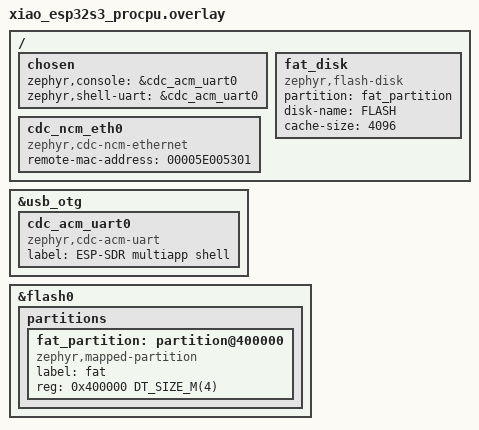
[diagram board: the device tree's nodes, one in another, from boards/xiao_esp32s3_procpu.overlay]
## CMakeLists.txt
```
# SPDX-License-Identifier: GPL-3.0-or-later
#
# multiapp (doc/multiapp.md): the other apps, built from their own sources as
# llext extensions, run on one host image.

cmake_minimum_required(VERSION 3.20.0)

find_package(Zephyr REQUIRED HINTS $ENV{ZEPHYR_BASE})
project(esp_sdr_multiapp)

include(${CMAKE_CURRENT_LIST_DIR}/../common/common.cmake)

target_include_directories(app PRIVATE include src)
target_sources(app PRIVATE src/main.c src/apps.c src/drive.c)

# Zephyr drops -Os from Xtensa extensions (cmake/compiler/gcc/target_xtensa.cmake);
# unoptimized, they need several times the stack and code.
list(REMOVE_ITEM LLEXT_REMOVE_FLAGS -Os)

set(apps_dir ${CMAKE_CURRENT_LIST_DIR}/..)
set(ext_dir ${PROJECT_BINARY_DIR}/llext)
set(ext_names)
set(ext_libs)
set(ext_files)
# The build id every app file carries (buildid.py, generated below).
set(build_id_bin ${ext_dir}/multiapp_build_id.bin)
set(build_id_h ${ext_dir}/multiapp_build_id.h)

# multiapp_extension(<name> SOURCES <files> [APP <dir>] [STACK <bytes>]
#                    [USB <MULTIAPP_USB_* mask>] [AREA])
#
# The extension <name>, include/multiapp/ext.h in front of each source. APP:
# the app's directory, for its CONFIG_APP_* values (appconfig.py). AREA: it
# has buffers in the area (ESP_SDR_HIGH_BUF_DEFINE()).
function(multiapp_extension name)
  cmake_parse_arguments(EXT "AREA" "APP;STACK;USB" "SOURCES" ${ARGN})
  if(NOT EXT_STACK)
    set(EXT_STACK 2048)
  endif()
  if(NOT EXT_USB)
    set(EXT_USB 0)
  endif()
  set(info ${ext_dir}/${name}_info.c)
  file(WRITE ${info}.tmp
    "/* Generated by apps/multiapp/CMakeLists.txt. */\n"
    "#include <zephyr/llext/symbol.h>\n"
    "#include <multiapp/multiapp.h>\n\n"
    "int main(void);\n\n"
    "const struct multiapp_info multiapp_info = {\n"
    "\t.abi = MULTIAPP_ABI,\n"
    "\t.name = \"${name}\",\n"
    "\t.main = main,\n"
    "};\n"
    "EXPORT_SYMBOL(multiapp_info);\n")
  configure_file(${info}.tmp ${info} COPYONLY)

  add_llext_target(${name}_ext
    OUTPUT  ${ext_dir}/${name}.llext
    SOURCES ${EXT_SOURCES} ${info}
  )
  # C only: an app may have assembly sources (link's esp-dsp FFT kernel).
  llext_compile_options(${name}_ext
    "$<$<COMPILE_LANGUAGE:C>:SHELL:-include ${CMAKE_CURRENT_FUNCTION_LIST_DIR}/include/multiapp/ext.h>")
  if(EXT_APP)
    set(app_config ${ext_dir}/${name}_config.h)
    set(app_confs ${EXT_APP}/Kconfig ${EXT_APP}/prj.conf)
    set(conf_args --conf ${EXT_APP}/prj.conf)
    # multiapp is built for the XIAO ESP32-S3 only.
    if(EXISTS ${EXT_APP}/boards/xiao_esp32s3_procpu.conf)
      list(APPEND app_confs ${EXT_APP}/boards/xiao_esp32s3_procpu.conf)
      list(APPEND conf_args --conf ${EXT_APP}/boards/xiao_esp32s3_procpu.conf)
    endif()
    execute_process(
      COMMAND ${PYTHON_EXECUTABLE} ${CMAKE_CURRENT_FUNCTION_LIST_DIR}/appconfig.py
              --kconfig ${EXT_APP}/Kconfig --host-config ${DOTCONFIG} ${conf_args}
              --out ${app_config}
      RESULT_VARIABLE ret
    )
    if(ret)
      message(FATAL_ERROR "multiapp: ${name}: appconfig.py failed")
    endif()
    set_property(DIRECTORY APPEND PROPERTY CMAKE_CONFIGURE_DEPENDS
      ${app_confs} ${CMAKE_CURRENT_FUNCTION_LIST_DIR}/appconfig.py)
    llext_compile_options(${name}_ext "$<$<COMPILE_LANGUAGE:C>:SHELL:-include ${app_config}>")
  endif()
  llext_compile_definitions(${name}_ext MULTIAPP_NAME=${name})
  llext_include_directories(${name}_ext
    ${CMAKE_CURRENT_FUNCTION_LIST_DIR}/include
    ${apps_dir}/common/include
  )
  # The file the host loads: the extension and its trailer (apptrail.py).
  set(file ${ext_dir}/files/${name}.llext)
  add_custom_command(
    OUTPUT ${file}
    COMMAND ${CMAKE_COMMAND} -E make_directory ${ext_dir}/files
    COMMAND ${PYTHON_EXECUTABLE} ${CMAKE_CURRENT_FUNCTION_LIST_DIR}/apptrail.py
            --stack ${EXT_STACK} --build-id ${build_id_bin} ${ext_dir}/${name}.llext ${file}
    DEPENDS ${CMAKE_CURRENT_FUNCTION_LIST_DIR}/apptrail.py ${ext_dir}/${name}.llext
            ${build_id_bin}
  )
  generate_inc_file_for_target(app ${file}
    ${ZEPHYR_BINARY_DIR}/include/generated/multiapp_${name}.inc)

  set(ext_names ${ext_names} ${name} PARENT_SCOPE)
  set(ext_usb_${name} ${EXT_USB} PARENT_SCOPE)
  if(EXT_AREA)
    set(ext_area_${name} true PARENT_SCOPE)
  else()
    set(ext_area_${name} false PARENT_SCOPE)
  endif()
  set(ext_libs ${ext_libs} $<TARGET_FILE:${name}_ext_llext_lib> PARENT_SCOPE)
  set(ext_files ${ext_files} ${file} PARENT_SCOPE)
endfunction()

multiapp_extension(hello SOURCES ${CMAKE_CURRENT_LIST_DIR}/ext/hello.c)
multiapp_extension(capture STACK 4096 SOURCES ${apps_dir}/capture/src/main.c)
multiapp_extension(rfprobe STACK 2048 SOURCES ${apps_dir}/rfprobe/src/main.c)
multiapp_extension(wpan STACK 1536 SOURCES ${apps_dir}/wpan/src/main.c)
set(stream ${apps_dir}/stream/src)
multiapp_extension(stream APP ${apps_dir}/stream STACK 2048 USB 1 # MULTIAPP_USB_NCM
  SOURCES ${stream}/main.c ${stream}/vrt_rx.c ${stream}/iq_pack.c
          ${stream}/shell.c ${stream}/vrt_tx.c ${stream}/transport_udp.c)
set_source_files_properties(${stream}/iq_pack.c PROPERTIES COMPILE_OPTIONS -O3)

# osmosdr: its vendor USB class is in the host (src/osmosdr.c), the rest an
# extension whose USB blocks and ring and USB thread stacks are in the area.
set(osmosdr ${apps_dir}/osmosdr/src)
multiapp_extension(osmosdr APP ${apps_dir}/osmosdr STACK 1536 USB 2 AREA # MULTIAPP_USB_VENDOR
  SOURCES ${osmosdr}/main.c ${osmosdr}/sdr.c ${osmosdr}/shell.c)
set_source_files_properties(${osmosdr}/sdr.c PROPERTIES COMPILE_OPTIONS "-O3;-ffp-contract=fast")
target_sources(app PRIVATE src/osmosdr.c ${osmosdr}/usb_sdr.c)
set_source_files_properties(src/osmosdr.c ${osmosdr}/usb_sdr.c PROPERTIES
  INCLUDE_DIRECTORIES ${osmosdr})

# link, with the flags of its own build (apps/link/CMakeLists.txt).
set(link ${apps_dir}/link/src)
set(esp_dsp ${WEST_TOPDIR}/modules/lib/esp-dsp)
set(esp_dsp_fft ${esp_dsp}/modules/fft/float/dsps_fft2r_fc32_aes3_.S)
multiapp_extension(link APP ${apps_dir}/link STACK 2048
  SOURCES ${link}/main.c ${link}/mac.c ${link}/perf.c ${link}/qam.c ${link}/rs.c
          ${link}/hamming.c ${link}/ofdm.c ${link}/ofdm_frame.c ${link}/ofdm_test.c
          ${esp_dsp_fft})
llext_compile_definitions(link_ext QAM_SPS=CONFIG_APP_SPS)
set_source_files_properties(${link}/qam.c ${link}/ofdm.c PROPERTIES
  COMPILE_OPTIONS "-O3;-ffp-contract=fast")
set_source_files_properties(${link}/rs.c ${link}/hamming.c PROPERTIES COMPILE_OPTIONS -O3)
set_source_files_properties(${esp_dsp_fft} PROPERTIES
  COMPILE_DEFINITIONS CONFIG_IDF_TARGET_ESP32S3=1
  INCLUDE_DIRECTORIES ${esp_dsp}/modules/fft/include)

# Buffers of the apps that never run the receive ring, in its bank 0.
zephyr_linker_sources(DATA_SECTIONS multiapp_bank0.ld)

# The FAT volume with the extensions' files (src/drive.c), for west dfu --storage.
dt_nodelabel(fat_node NODELABEL fat_partition)
dt_reg_size(fat_size PATH ${fat_node})
set(fat_img ${PROJECT_BINARY_DIR}/multiapp_fat.img)
add_custom_command(
  OUTPUT ${fat_img}
  COMMAND ${PYTHON_EXECUTABLE} ${CMAKE_CURRENT_LIST_DIR}/mkfat.py --size ${fat_size}
          --out ${fat_img} ${ext_files}
  DEPENDS ${CMAKE_CURRENT_LIST_DIR}/mkfat.py ${ext_files}
  COMMENT "FAT volume of the multiapp extensions"
)
add_custom_target(multiapp_fat ALL DEPENDS ${fat_img})

# The embedded extensions, and what the host exports to them.
set(embedded ${ext_dir}/embedded.c)
set(embedded_text "/* Generated by apps/multiapp/CMakeLists.txt. */\n\n#include \"apps.h\"\n#include <multiapp/multiapp.h>\n\n")
# Without CONFIG_MULTIAPP_EMBEDDED the table keeps only what a boot needs
# before it loads the app's file (name, USB profile, area).
if(CONFIG_MULTIAPP_EMBEDDED)
  foreach(name ${ext_names})
    string(APPEND embedded_text
      "static const uint8_t ${name}_llext[] __aligned(4) = {\n#include \"multiapp_${name}.inc\"\n};\n")
  endforeach()
endif()
string(APPEND embedded_text "\nconst struct multiapp_embedded multiapp_embedded[] = {\n")
foreach(name ${ext_names})
  if(CONFIG_MULTIAPP_EMBEDDED)
    set(elf "${name}_llext, sizeof(${name}_llext)")
  else()
    set(elf "NULL, 0")
  endif()
  string(APPEND embedded_text
    "\t{\"${name}\", ${elf}, ${ext_usb_${name}}, ${ext_area_${name}}},\n")
endforeach()
list(LENGTH ext_names ext_count)
string(APPEND embedded_text "};\n\nconst size_t multiapp_embedded_count = ${ext_count};\n")
file(WRITE ${embedded}.tmp "${embedded_text}")
configure_file(${embedded}.tmp ${embedded} COPYONLY)

set(exports ${ext_dir}/exports.c)
set(logs ${ext_dir}/logs.c)
set(objects ${ext_dir}/objects.c)
add_custom_command(
  OUTPUT ${exports} ${logs} ${objects}
  COMMAND ${PYTHON_EXECUTABLE} ${CMAKE_CURRENT_LIST_DIR}/exports.py
          --exports ${exports} --logs ${logs} --objects ${objects}
          --area-size ${CONFIG_MULTIAPP_AREA_SIZE} ${ext_libs}
  DEPENDS ${CMAKE_CURRENT_LIST_DIR}/exports.py ${ext_libs}
  COMMENT "Exporting what the multiapp extensions import"
)
target_sources(app PRIVATE ${embedded} ${exports} ${logs} ${objects})

# The build id (buildid.py): a hash of what host and extensions must agree on.
set(id_dirs ${ZEPHYR_BASE}/include ${CMAKE_CURRENT_LIST_DIR}/include ${apps_dir}/common/include
            ${apps_dir}/../include)
set(id_headers)
set(id_args)
foreach(dir ${id_dirs})
  file(GLOB_RECURSE headers ${dir}/*.h)
  list(APPEND id_headers ${headers})
  list(APPEND id_args --dir ${dir})
endforeach()
add_custom_command(
  OUTPUT ${build_id_h} ${build_id_bin}
  COMMAND ${PYTHON_EXECUTABLE} ${CMAKE_CURRENT_LIST_DIR}/buildid.py
          --out-h ${build_id_h} --out-bin ${build_id_bin}
          --compiler "${CMAKE_C_COMPILER_ID} ${CMAKE_C_COMPILER_VERSION}"
          --file ${AUTOCONF_H} --file ${DEVICETREE_GENERATED_H} --file ${exports} ${id_args}
  DEPENDS ${CMAKE_CURRENT_LIST_DIR}/buildid.py ${AUTOCONF_H} ${DEVICETREE_GENERATED_H}
          ${exports} ${id_headers}
  COMMENT "multiapp build id"
)
target_sources(app PRIVATE ${build_id_h})
target_include_directories(app PRIVATE ${ext_dir})
```

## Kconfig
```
# SPDX-License-Identifier: GPL-3.0-or-later

mainmenu "multiapp: one firmware that runs the others"

config MULTIAPP_INSTR_HEAP_KB
	int "Extension code heap in PSRAM, KiB"
	default 256

config MULTIAPP_DATA_HEAP_KB
	int "Extension data heap in PSRAM, KiB"
	default 512
	help
	  The extensions' data, read-only data and bss, and llext's metadata.

config MULTIAPP_STACK_SIZE
	int "Largest stack of an app's main() thread"
	default 4096
	help
	  One stack in PSRAM for every app's main(); an app that asks for more
	  (multiapp_extension() STACK) is refused.

config MULTIAPP_EMBEDDED
	bool "Apps built into the image too"
	default y
	help
	  Each app is also built into the image, loaded when the FAT volume has
	  no good file for it. Without, an app runs only from its file.

config MULTIAPP_FILE_MAX_KB
	int "Largest app file, KiB"
	default 192
	help
	  The PSRAM buffer a boot reads the app's file into before loading it.

config MULTIAPP_AREA_SIZE
	int "Bytes of internal RAM the apps share, one per boot"
	default 24576
	help
	  In the high region: the buffers an app defines with
	  ESP_SDR_HIGH_BUF_DEFINE() and ESP_SDR_HIGH_STACK_DEFINE() (osmosdr's
	  USB blocks, ring and USB thread stacks), or in other boots the 802.15.4
	  driver's buffers.

config MULTIAPP_AUTOSTART
	string "App to start at boot"
	default ""
	help
	  Started when no "app run" request is pending from before a reset.
	  Empty: none, start one with "app run <name>".

config LLEXT_EXPORT_SYMBOL_GROUP_MULTIAPP
	def_bool y
	help
	  What the embedded extensions import, exported by exports.py. Zephyr's
	  default groups (every syscall, a libc subset) stay off: what they
	  export is kept by the linker, kernel code in IRAM included.

# USB shell and DFU.
rsource "../common/Kconfig"
source "samples/subsys/usb/common/Kconfig.sample_usbd"

source "Kconfig.zephyr"
```

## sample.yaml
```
sample:
  name: ESP-SDR multiapp
  description: >-
    One firmware that runs the other apps as loadable extensions
    (doc/multiapp.md): capture, rfprobe, wpan, stream, osmosdr and link,
    loaded from files on a FAT volume, with built-in copies
common:
  tags: esp-sdr
  sysbuild: true
  platform_allow:
    - xiao_esp32s3/esp32s3/procpu
  integration_platforms:
    - xiao_esp32s3/esp32s3/procpu
tests:
  # The console is on USB CDC-ACM; "app run <name>" there (see README).
  sample.esp_sdr.multiapp:
    build_only: true
  # On the desk with the boards attached (pytest/test_multiapp.py): the image and
  # its FAT volume (scripts/twister-flash.py), booting into hello from its file.
  sample.esp_sdr.multiapp.hil:
    harness: pytest
    harness_config:
      pytest_dut_scope: module
    extra_args:
      - multiapp_EXTRA_CONF_FILE=hil.conf
    timeout: 600
```

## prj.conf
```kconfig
# The Wi-Fi driver brings the radio up at boot; nothing may scan or connect.
CONFIG_NETWORKING=y
CONFIG_WIFI=y
CONFIG_ESP32_WIFI_STA_POWER_SAVE_NONE=y
CONFIG_ESP_SDR=y

CONFIG_SHELL=y
CONFIG_LOG=y
CONFIG_LOG_MODE_DEFERRED=y

# Loadable extensions, code and data in PSRAM heaps; the code runs at its
# instruction bus alias (src/apps.c).
CONFIG_LLEXT=y
CONFIG_LLEXT_HEAP_DYNAMIC=y
CONFIG_LLEXT_EXEC_ALIAS=y
# Every global of an extension, not only EXPORT_SYMBOL()s: the host finds the
# hooks an app defines by name (app_usb_dfu_prepare()).
CONFIG_LLEXT_IMPORT_ALL_GLOBALS=y
# The host exports exactly what its extensions import (exports.py, group MULTIAPP).
CONFIG_LLEXT_EXPORT_DEFAULT_GROUPS=n
CONFIG_LLEXT_LOG_LEVEL_ERR=y

# What the apps need from the host: capture's float output, rfprobe's dumps.
CONFIG_PICOLIBC_IO_FLOAT=y
CONFIG_BASE64=y
```

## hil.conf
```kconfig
# The desk check (sample.esp_sdr.multiapp.hil): every boot starts hello.
CONFIG_MULTIAPP_AUTOSTART="hello"
```

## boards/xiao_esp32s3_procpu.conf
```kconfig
# SMP and octal PSRAM as the apps that run on both cores (stream, link,
# osmosdr, wpan); the Wi-Fi heap goes to PSRAM.
CONFIG_FPU=y
CONFIG_FPU_SHARING=y
CONFIG_SMP=y
CONFIG_ESP_SPIRAM=y
CONFIG_SPIRAM_MODE_OCT=y
CONFIG_ESP_WIFI_HEAP_SPIRAM=y
# The network and Wi-Fi drivers' stacks and packet pools too: internal RAM
# is for the dump banks.
CONFIG_ESP32_WIFI_NET_ALLOC_SPIRAM=y
CONFIG_SCHED_CPU_MASK=y
# The apps use the radio, not Wi-Fi traffic: the fewest static receive buffers
# (about 1.6 KB of system heap each), so no A-MPDU receive, whose window may be
# at most twice their number.
CONFIG_ESP32_WIFI_STATIC_RX_BUFFER_NUM=2
CONFIG_ESP32_WIFI_AMPDU_RX_ENABLED=n
CONFIG_ESP32_WIFI_MGMT_SBUF_NUM=8
CONFIG_ESP32_WIFI_EVENT_TASK_STACK_SIZE=1024
CONFIG_NET_MGMT_EVENT_STACK_SIZE=1024
CONFIG_HEAP_MEM_POOL_IGNORE_MIN=y
# Peak 12216 bytes in every app (`kernel heap`), nearly all of it the Wi-Fi driver's.
CONFIG_HEAP_MEM_POOL_SIZE=13312
CONFIG_SYS_HEAP_RUNTIME_STATS=y
CONFIG_RESET_ON_FATAL_ERROR=y
# A hung app resets the board instead of needing a replug; "app crash" tells.
CONFIG_APP_LIVENESS_WATCHDOG=y

# USB device on the OTG port: shell on CDC-ACM, DFU with sysbuild/MCUboot.
CONFIG_USB_DEVICE_STACK_NEXT=y
CONFIG_SAMPLE_USBD_PRODUCT="ESP-SDR multiapp"
CONFIG_SAMPLE_USBD_PID=0x0005
CONFIG_USBD_LOG_LEVEL_WRN=y
CONFIG_UDC_DRIVER_LOG_LEVEL_WRN=y
CONFIG_USBD_CDC_ACM_CLASS=y
# CDC-ACM carries the console and the shell: its own logging must stay off
# (doc/testing.md: usbd_cdc_acm.c's #warning is fatal under twister).
CONFIG_USBD_CDC_ACM_LOG_LEVEL_OFF=y
CONFIG_CDC_ACM_SERIAL_INITIALIZE_AT_BOOT=n
CONFIG_LOG_BACKEND_UART=n
CONFIG_USBD_CDC_ACM_WORKQUEUE=y
CONFIG_KERNEL_SHELL=y
CONFIG_SHELL_BACKEND_SERIAL_LOG_MESSAGE_QUEUE_SIZE=256
CONFIG_HWINFO=y

# The radio as wpan uses it: transmit through the DAC, the gapless receive ring
# (three dump banks: the DRAM image must end below 0x3fcb0000) and the
# 802.15.4 software radio without the L2.
CONFIG_ESP_SDR_TX=y
CONFIG_ESP_SDR_TX_DAC=y
CONFIG_ESP_SDR_TX_DAC_HIGH_RAM=y
CONFIG_ESP_SDR_RING=y
CONFIG_ESP_SDR_IEEE802154=y
# Its buffers live in the area osmosdr's boots use instead (src/apps.c).
CONFIG_ESP_SDR_IEEE802154_HIGH_RAM_APP=y
CONFIG_IEEE802154=y
CONFIG_NET_L2_IEEE802154=n
CONFIG_NET_L2_WIFI_SHELL=n

# Internal RAM for the three banks: stacks sized for an 80 % peak with every app
# exercised (`kernel thread stacks`, `app info`, `app crash`).
CONFIG_NET_RX_STACK_SIZE=1024
# Peak 1120 (radio init), in every boot.
CONFIG_MAIN_STACK_SIZE=1536
# Peak 880 (stream).
CONFIG_SYSTEM_WORKQUEUE_STACK_SIZE=1152
# Peak 288.
CONFIG_IDLE_STACK_SIZE=384
# Peak 560.
CONFIG_ISR_STACK_SIZE=768
# The apps' commands run here: link's need 2.3 KB (ofdm bench), as its own.
CONFIG_SHELL_STACK_SIZE=3072
# Peak 544.
CONFIG_LOG_PROCESS_THREAD_STACK_SIZE=704
# Peak 688.
CONFIG_ESP32_TIMER_TASK_STACK_SIZE=896
CONFIG_LOG_BUFFER_SIZE=448
CONFIG_SHELL_CMD_BUFF_SIZE=96
CONFIG_SHELL_HISTORY=n
CONFIG_DEVICE_SHELL=n
CONFIG_DATE_SHELL=n
# Peak 1008, in a DFU download (it writes the flash).
CONFIG_USBD_THREAD_STACK_SIZE=1280
# Peak 528.
CONFIG_UDC_DWC2_STACK_SIZE=704
# Peak 640.
CONFIG_USBD_CDC_ACM_STACK_SIZE=832
# llext links the whole kernel; nothing here sends mailbox messages.
CONFIG_NUM_MBOX_ASYNC_MSGS=0

# stream's USB profile: VITA 49.2 over UDP/IPv6 on CDC-NCM, with the
# network pools the stream app sizes (in PSRAM, see above). The NCM endpoint
# buffers live in bank 0 (multiapp_bank0.ld).
CONFIG_LIBVRT=y
CONFIG_USBD_CDC_NCM_CLASS=y
CONFIG_USBD_CDC_NCM_RECV_NTB_MAX_SIZE=8192
CONFIG_USBD_CDC_NCM_MAX_DGRAM_PER_NTB=5
CONFIG_USBD_CDC_NCM_SEND_NTB_MAX_SIZE=4608
CONFIG_USBD_CDC_NCM_SEND_MAX_DGRAM_PER_NTB=3
CONFIG_NET_IPV6=y
CONFIG_NET_IPV4=n
CONFIG_NET_UDP=y
CONFIG_NET_SOCKETS=y
CONFIG_NET_CONTEXT_RCVTIMEO=y
CONFIG_NET_IF_MAX_IPV6_COUNT=2
CONFIG_NET_BUF_DATA_SIZE=256
CONFIG_NET_PKT_TX_COUNT=24
CONFIG_NET_BUF_TX_COUNT=32
CONFIG_NET_PKT_RX_COUNT=16
CONFIG_NET_BUF_RX_COUNT=48
CONFIG_NET_STATISTICS=y
CONFIG_NET_STATISTICS_PER_INTERFACE=y
CONFIG_NET_SHELL=y
# Two sockets on one link: fewer contexts and neighbours than the defaults.
CONFIG_NET_MAX_CONTEXTS=4
CONFIG_NET_IPV6_MAX_NEIGHBORS=4

# The apps as files on a FAT volume (src/drive.c): read only, by the host,
# before USB starts; long names (".llext" is not 8.3), one file at a time.
CONFIG_FILE_SYSTEM=y
CONFIG_FAT_FILESYSTEM_ELM=y
CONFIG_FS_FATFS_MOUNT_MKFS=n
CONFIG_FS_FATFS_NUM_FILES=1
CONFIG_FS_FATFS_NUM_DIRS=1
CONFIG_FS_FATFS_LFN=y
CONFIG_FS_FATFS_LFN_MODE_BSS=y
CONFIG_FS_FATFS_MAX_LFN=32
CONFIG_DISK_DRIVER_FLASH=y
CONFIG_FLASHDISK_LOG_LEVEL_WRN=y
CONFIG_FS_LOG_LEVEL_WRN=y
# The app files' CRC (crc32_ieee()).
CONFIG_CRC=y
# The volume as a USB drive in boots without an app: one SCSI buffer (in
# bank 0), the thread writes the flash so its stack stays internal (peak 880).
CONFIG_USBD_MSC_CLASS=y
CONFIG_USBD_MSC_DOUBLE_BUFFERING=n
CONFIG_USBD_MSC_STACK_SIZE=1152
CONFIG_USBD_MSC_LOG_LEVEL_WRN=y
```

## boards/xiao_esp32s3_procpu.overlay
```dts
/*
 * SPDX-License-Identifier: GPL-3.0-or-later
 */

/ {
	chosen {
		zephyr,console = &cdc_acm_uart0;
		zephyr,shell-uart = &cdc_acm_uart0;
	};

	/* The apps as files: the FAT volume, block device "FLASH". */
	fat_disk: fat_disk {
		compatible = "zephyr,flash-disk";
		partition = <&fat_partition>;
		disk-name = "FLASH";
		cache-size = <4096>;
	};

	/* stream's USB network function; the host side gets MAC 00:00:5e:00:53:01. */
	cdc_ncm_eth0: cdc_ncm_eth0 {
		compatible = "zephyr,cdc-ncm-ethernet";
		remote-mac-address = "00005E005301";
	};
};

zephyr_udc0: &usb_otg {
	status = "okay";

	/* Console, shell and logs while OTG owns the USB port. */
	cdc_acm_uart0: cdc_acm_uart0 {
		compatible = "zephyr,cdc-acm-uart";
		label = "ESP-SDR multiapp shell";
	};
};

/* The upper half of the 8 MB flash, which the board's 4 MB partition table leaves out. */
&flash0 {
	partitions {
		fat_partition: partition@400000 {
			compatible = "zephyr,mapped-partition";
			label = "fat";
			reg = <0x400000 DT_SIZE_M(4)>;
		};
	};
};
```

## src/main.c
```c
/*
 * SPDX-License-Identifier: GPL-3.0-or-later
 *
 * multiapp host (doc/multiapp.md): the USB shell and DFU, the radio, and the
 * apps built as extensions (apps.c).
 */

#include <zephyr/app_version.h>
#include <zephyr/kernel.h>

#include <esp_sdr/esp_sdr.h>

#include "app_cpu.h"
#include "app_usb.h"
#include "apps.h"

int main(void)
{
	int ret;

	printk("multiapp %s\n", APP_VERSION_STRING);
	/* Before USB: its interrupt lands on the CPU that allocates it, CPU 1 is the radio's. */
	app_cpu_pin_system_threads(0);
	ret = esp_sdr_init();
	if (ret != 0) {
		printk("multiapp: radio init failed (%d)\n", ret);
	}
	printk("multiapp: ready\n");
	/*
	 * The files while bank 0 and the flash are the host's alone, then the app
	 * before USB, whose classes call its handlers (osmosdr's).
	 */
	(void)multiapp_drive_scan();
	if (!multiapp_boot()) {
		/* No app: the volume goes to the PC as a USB drive. */
		(void)multiapp_drive_export();
	}
	/* The USB shell and DFU, and the trial watchdog that reverts an image that hangs. */
	if (app_usb_init() != 0) {
		printk("multiapp: usb init failed\n");
	}
	multiapp_note_main_stack();
	return 0;
}
```

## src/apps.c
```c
/*
 * SPDX-License-Identifier: GPL-3.0-or-later
 *
 * Runs one app per boot as an llext extension (doc/multiapp.md): loads it
 * into PSRAM, runs its constructors (include/multiapp/ext.h) and starts its
 * main() in a thread. Starting another app reboots into it.
 */

#include <errno.h>
#include <stdio.h>
#include <string.h>

#include <zephyr/app_version.h>
#include <zephyr/init.h>
#include <zephyr/kernel.h>
#include <zephyr/llext/buf_loader.h>
#include <zephyr/llext/llext.h>
#include <zephyr/logging/log.h>
#include <zephyr/shell/shell.h>
#include <zephyr/sys/crc.h>
#include <zephyr/sys/reboot.h>
#include <zephyr/usb/usbd.h>

#include <esp_attr.h>
#include <esp_rom_sys.h>
#include <rom/cache.h>

#include <esp_sdr/esp_sdr.h>
#if defined(CONFIG_ESP_SDR_IEEE802154)
#include <esp_sdr/ieee154_esp_sdr.h>
#endif

#include <multiapp/multiapp.h>

#include "multiapp_build_id.h"

#include "app_crash.h"
#include "app_usb.h"
#include "apps.h"

LOG_MODULE_REGISTER(multiapp, LOG_LEVEL_INF);

/* One MMU table maps both buses: PSRAM at 0x3c000000 + x executes at 0x42000000 + x. */
#define IBUS_DBUS_OFFSET 0x06000000

#define ROOTS_MAX       4
#define REQUEST_MAGIC   0x6d617070U /* "mapp" */
#define TRIED_MAGIC     0x74726964U /* "trid": the boot that tried it has started */
#define REBOOT_DELAY_MS 100

static EXT_RAM_BSS_ATTR uint8_t instr_heap[KB(CONFIG_MULTIAPP_INSTR_HEAP_KB)] __aligned(64);
static EXT_RAM_BSS_ATTR uint8_t data_heap[KB(CONFIG_MULTIAPP_DATA_HEAP_KB)] __aligned(64);

/* PSRAM like the app's data: internal RAM is kept for the dump banks. */
static Z_KERNEL_STACK_DEFINE_IN(app_stack, CONFIG_MULTIAPP_STACK_SIZE, EXT_RAM_BSS_ATTR);
static struct k_thread app_thread;

static EXT_RAM_BSS_ATTR struct llext_buf_loader loader;
static struct llext *loaded;
static const struct multiapp_info *loaded_info;
static const char *loaded_source; /* "file" or "built-in" */

/* What this host's apps carry in their trailers (buildid.py). */
static const uint8_t build_id[] = MULTIAPP_BUILD_ID;

/* The app's file, read whole before llext sees it (drive.c). */
static EXT_RAM_BSS_ATTR uint8_t file_buf[KB(CONFIG_MULTIAPP_FILE_MAX_KB)] __aligned(4);
static const struct shell_static_entry *roots[ROOTS_MAX];
static size_t root_count;

/* The app for the next boot and how far its boot got; survives a software reset. */
static RTC_NOINIT_ATTR struct {
	uint32_t magic;
	char name[24];
	uint32_t step;
} request;

enum boot_step {
	STEP_REQUESTED,
	STEP_LOADING,
	STEP_CONSTRUCTORS,
	STEP_MAIN,
	STEP_RUNNING,
};

static const char *const step_names[] = {"requested", "loading", "constructors", "main",
					 "running"};

/* What the previous boot left: the request it tried and the step it reached. */
static char tried_name[sizeof(request.name)];
static uint32_t tried_step;
static bool tried;

/* This boot's app, from a request or CONFIG_MULTIAPP_AUTOSTART, and its USB profile. */
static char boot_name[sizeof(request.name)];
static uint32_t usb_profile;
static int boot_ret;

/*
 * Internal RAM for one user per boot: the boot's app if it has buffers there
 * (ESP_SDR_HIGH_BUF_DEFINE(), exports.py), else the 802.15.4 driver.
 */
uint8_t multiapp_area[CONFIG_MULTIAPP_AREA_SIZE] __aligned(16) ESP_SDR_HIGH_RAM;
static const struct multiapp_embedded *area_app;

#if defined(CONFIG_ESP_SDR_IEEE802154_HIGH_RAM_APP)
void *ieee154_esp_sdr_high_ram(size_t size)
{
	if (area_app != NULL || size > sizeof(multiapp_area)) {
		return NULL;
	}
	return multiapp_area;
}
#endif

/* Before the devices: the area's user and the USB profile follow the boot's app. */
static int boot_pick(void)
{
	const struct multiapp_embedded *app;

	if (request.magic == TRIED_MAGIC) {
		/* The boot that tried an app ended before "app run" or a reset: report it. */
		tried = true;
		tried_step = request.step;
		memcpy(tried_name, request.name, sizeof(tried_name));
		tried_name[sizeof(tried_name) - 1] = '\0';
		request.magic = 0;
	}
	if (request.magic == REQUEST_MAGIC) {
		request.magic = TRIED_MAGIC;
		request.step = STEP_REQUESTED;
		memcpy(boot_name, request.name, sizeof(boot_name));
		boot_name[sizeof(boot_name) - 1] = '\0';
	} else if (!(tried && tried_step < STEP_RUNNING &&
		     strcmp(tried_name, CONFIG_MULTIAPP_AUTOSTART) == 0)) {
		/* Tried like a request, so one that never gets running is skipped once. */
		strncpy(boot_name, CONFIG_MULTIAPP_AUTOSTART, sizeof(boot_name) - 1);
		if (boot_name[0] != '\0') {
			request.magic = TRIED_MAGIC;
			request.step = STEP_REQUESTED;
			memcpy(request.name, boot_name, sizeof(request.name));
		}
	}
	app = multiapp_embedded_find(boot_name);
	usb_profile = app != NULL ? app->usb : MULTIAPP_USB_MSC;
	area_app = app != NULL && app->area ? app : NULL;
	return 0;
}
SYS_INIT(boot_pick, PRE_KERNEL_1, 0);

static int heaps_init(void)
{
	return llext_heap_init_harvard_exec(instr_heap, sizeof(instr_heap), data_heap,
					    sizeof(data_heap), IBUS_DBUS_OFFSET);
}
SYS_INIT(heaps_init, APPLICATION, 0);

/* Only the boot's app's classes: the OTG controller has too few IN endpoints for all. */
void app_usb_classes(struct usbd_context *ctx)
{
	if (IS_ENABLED(CONFIG_USBD_CDC_NCM_CLASS) && (usb_profile & MULTIAPP_USB_NCM) == 0U) {
		(void)usbd_unregister_class(ctx, "cdc_ncm_0", USBD_SPEED_FS, 1);
	}
	if ((usb_profile & MULTIAPP_USB_VENDOR) == 0U) {
		(void)usbd_unregister_class(ctx, "esp_sdr_usb", USBD_SPEED_FS, 1);
	}
	if (IS_ENABLED(CONFIG_USBD_MSC_CLASS) && (usb_profile & MULTIAPP_USB_MSC) == 0U) {
		(void)usbd_unregister_class(ctx, "msc_0", USBD_SPEED_FS, 1);
	}
}

void multiapp_shell_register(const struct shell_static_entry *root)
{
	if (root_count == ARRAY_SIZE(roots)) {
		LOG_ERR("no room for root command %s", root->syntax);
		return;
	}
	roots[root_count++] = root;
}

static const struct shell_static_entry *root_find(const char *name)
{
	for (size_t i = 0; i < root_count; i++) {
		if (strcmp(roots[i]->syntax, name) == 0) {
			return roots[i];
		}
	}
	return NULL;
}

const struct multiapp_embedded *multiapp_embedded_find(const char *name)
{
	for (size_t i = 0; i < multiapp_embedded_count; i++) {
		if (strcmp(multiapp_embedded[i].name, name) == 0) {
			return &multiapp_embedded[i];
		}
	}
	return NULL;
}

/* llext wrote the code through the data bus, and the ESP cache driver has no icache ops. */
static void sync_text(const struct llext *ext)
{
	uintptr_t text = (uintptr_t)ext->mem[LLEXT_MEM_TEXT];
	size_t size = ext->mem_size[LLEXT_MEM_TEXT];

	Cache_WriteBack_Addr(text, size);
	Cache_Invalidate_Addr(text + IBUS_DBUS_OFFSET, size);
}

/* Record how far this boot's app got, until the next "app run" or reset. */
static void boot_step(enum boot_step step)
{
	if (request.magic == TRIED_MAGIC) {
		request.step = step;
	}
}

static void app_main(void *p1, void *p2, void *p3)
{
	int (*entry)(void) = p1;
	int ret;

	ARG_UNUSED(p2);
	ARG_UNUSED(p3);
	ret = entry();
	boot_step(STEP_RUNNING);
	LOG_INF("%s: main returned %d", loaded_info->name, ret);
}

/* The ELF size and stack of an app file whose trailer holds (apptrail.py); else -errno. */
static int check_trailer(const char *name, const char *source, const uint8_t *data, size_t len,
			 size_t *elf_size, uint32_t *stack_need)
{
	struct multiapp_trailer t;

	if (len < sizeof(t)) {
		LOG_ERR("%s (%s): %zu bytes, no trailer", name, source, len);
		return -ENOEXEC;
	}
	memcpy(&t, data + len - sizeof(t), sizeof(t));
	if (t.magic != MULTIAPP_TRAILER_MAGIC || t.elf_size != len - sizeof(t)) {
		LOG_ERR("%s (%s): no trailer for %zu bytes", name, source, len);
		return -ENOEXEC;
	}
	if (crc32_ieee(data, t.elf_size) != t.crc32) {
		LOG_ERR("%s (%s): CRC mismatch", name, source);
		return -EBADMSG;
	}
	BUILD_ASSERT(sizeof(build_id) == sizeof(t.build_id));
	if (memcmp(t.build_id, build_id, sizeof(build_id)) != 0) {
		LOG_ERR("%s (%s): built for host %02x%02x%02x%02x, this is %02x%02x%02x%02x", name,
			source, t.build_id[0], t.build_id[1], t.build_id[2], t.build_id[3],
			build_id[0], build_id[1], build_id[2], build_id[3]);
		return -ENOEXEC;
	}
	*elf_size = t.elf_size;
	*stack_need = t.stack_size;
	return 0;
}

int multiapp_start(const char *name)
{
	struct llext_load_param param = LLEXT_LOAD_PARAM_DEFAULT;
	const struct multiapp_embedded *app = multiapp_embedded_find(name);
	const struct multiapp_info *info;
	const uint8_t *data;
	int (*entry)(void);
	size_t stack, elf_size;
	uint32_t stack_need;
	ssize_t n;
	int ret;

	if (app == NULL) {
		return -ENOENT;
	}
	if (loaded != NULL) {
		return -EBUSY;
	}
	boot_step(STEP_LOADING);
	/* Its file if the volume has a good one, else the built-in copy. */
	n = multiapp_drive_status() == 0 ? multiapp_drive_read(name, file_buf, sizeof(file_buf))
					 : multiapp_drive_status();
	if (n >= 0 && check_trailer(name, "file", file_buf, n, &elf_size, &stack_need) == 0) {
		data = file_buf;
		loaded_source = "file";
	} else if (app->elf != NULL &&
		   check_trailer(name, "built-in", app->elf, app->size, &elf_size, &stack_need) == 0) {
		if (n != -ENOENT && n != -ENODEV) {
			LOG_WRN("%s: the file is not usable (%d), the built-in copy runs", name,
				(int)n);
		}
		data = app->elf;
		loaded_source = "built-in";
	} else {
		LOG_ERR("%s: no usable file (%d)%s", name, (int)n,
			app->elf != NULL ? " or built-in copy" : "");
		return n < 0 ? (int)n : -ENOEXEC;
	}
	stack = K_THREAD_STACK_SIZEOF(app_stack);
	if (stack_need > stack) {
		LOG_ERR("%s: needs a %u byte stack, the host has %zu (CONFIG_MULTIAPP_STACK_SIZE)",
			name, stack_need, stack);
		return -ENOMEM;
	}
	/*
	 * Temporary, so llext copies every region: in place, it would not relocate
	 * .got.loc, as .rela.dyn names no target section.
	 */
	loader = (struct llext_buf_loader)LLEXT_TEMPORARY_BUF_LOADER(data, elf_size);
	ret = llext_load(&loader.loader, app->name, &loaded, &param);
	if (ret != 0) {
		LOG_ERR("%s: load failed (%d)", name, ret);
		loaded = NULL;
		return ret;
	}
	sync_text(loaded);
	info = llext_find_sym(&loaded->exp_tab, "multiapp_info");
	if (info == NULL || info->abi != MULTIAPP_ABI) {
		LOG_ERR("%s: built for ABI %d, the host has %u", name,
			info != NULL ? (int)info->abi : -1, MULTIAPP_ABI);
		ret = -ENOEXEC;
		goto unload;
	}
	entry = info->main;
	if (entry == NULL) {
		LOG_ERR("%s: no main()", name);
		ret = -ENOEXEC;
		goto unload;
	}
	loaded_info = info;
	boot_step(STEP_CONSTRUCTORS);
	ret = llext_bringup(loaded);
	if (ret != 0) {
		LOG_ERR("%s: constructors failed (%d)", name, ret);
		goto unload;
	}
	LOG_INF("%s (%s): %zu bytes of code at %p, starting main()", name, loaded_source,
		loaded->mem_size[LLEXT_MEM_TEXT],
		(void *)((uintptr_t)loaded->mem[LLEXT_MEM_TEXT] + IBUS_DBUS_OFFSET));
	boot_step(STEP_MAIN);
	k_thread_create(&app_thread, app_stack, stack, app_main, entry, NULL, NULL,
			CONFIG_MAIN_THREAD_PRIORITY, 0, K_NO_WAIT);
	k_thread_name_set(&app_thread, info->name);
	return 0;

unload:
	/* Nothing of it has run yet, so it can go. */
	loaded_info = NULL;
	root_count = 0;
	llext_unload(&loaded);
	loaded = NULL;
	return ret;
}

#if defined(CONFIG_APP_USB_DFU)
/*
 * Before a DFU download writes flash: the loaded app's own hook, by name
 * (wpan stops its radio, which keeps a CPU from taking flash stall requests).
 */
void app_usb_dfu_prepare(void)
{
	void (*prepare)(void);

	if (loaded == NULL) {
		return;
	}
	prepare = llext_find_sym(&loaded->exp_tab, "app_usb_dfu_prepare");
	if (prepare != NULL) {
		prepare();
	}
}
#endif

static void reboot_handler(struct k_work *work)
{
	ARG_UNUSED(work);
	sys_reboot(SYS_REBOOT_WARM);
}
static K_WORK_DELAYABLE_DEFINE(reboot_work, reboot_handler);

int multiapp_request(const char *name)
{
	const struct multiapp_embedded *app = multiapp_embedded_find(name);

	if (app == NULL) {
		return -ENOENT;
	}
	if (loaded == NULL && app->usb == usb_profile && (!app->area || area_app == app)) {
		return multiapp_start(name);
	}
	/* An app cannot stop, USB enumerates once and the area has one user per boot. */
	request.magic = REQUEST_MAGIC;
	strncpy(request.name, name, sizeof(request.name) - 1);
	request.name[sizeof(request.name) - 1] = '\0';
	k_work_schedule(&reboot_work, K_MSEC(REBOOT_DELAY_MS));
	return 1;
}

bool multiapp_boot(void)
{
	int ret;

	if (boot_name[0] == '\0') {
		return false;
	}
	ret = multiapp_start(boot_name);
	if (ret != 0) {
		LOG_ERR("%s: not started (%d)", boot_name, ret);
		/* USB has not started: it comes up without the app's classes, with the drive. */
		usb_profile = MULTIAPP_USB_MSC;
	}
	/* Before the shell is open: "app info" tells. */
	boot_ret = ret;
	return ret == 0;
}

void *multiapp_app_fn(const char *name)
{
	return loaded != NULL ? (void *)llext_find_sym(&loaded->exp_tab, name) : NULL;
}

/* The host main()'s stack use, measured as it returns. */
static size_t main_used, main_size;

void multiapp_note_main_stack(void)
{
#if defined(CONFIG_INIT_STACKS) && defined(CONFIG_THREAD_STACK_INFO)
	size_t unused;

	if (k_thread_stack_space_get(k_current_get(), &unused) == 0) {
		main_size = k_current_get()->stack_info.size;
		main_used = main_size - unused;
	}
#endif
}

/* An app's app_usb_init() (include/multiapp/ext.h): the host's main() starts USB. */
int multiapp_ext_usb_init(void)
{
	return 0;
}

/*
 * Proxy roots: the apps' root commands by name, so the shell looks the same
 * as in the standalone app. The subcommands come from the loaded app's table.
 */
static void proxy_get(const char *name, size_t idx, struct shell_static_entry *entry)
{
	const struct shell_static_entry *root = root_find(name);
	const struct shell_static_entry *sub;

	entry->syntax = NULL;
	if (root == NULL || root->subcmd == NULL) {
		return;
	}
	sub = root->subcmd->entry;
	for (size_t i = 0; i <= idx; i++) {
		if (sub[i].syntax == NULL) {
			return;
		}
	}
	*entry = sub[idx];
}

static int proxy_cmd(const char *name, const struct shell *sh, size_t argc, char **argv)
{
	const struct shell_static_entry *root = root_find(name);

	if (root == NULL) {
		shell_error(sh, "%s: no loaded app has this command (app list)", name);
		return -ENOEXEC;
	}
	if (root->handler == NULL) {
		if (argc > 1) {
			shell_error(sh, "%s: unknown parameter: %s", name, argv[1]);
		}
		shell_help(sh);
		return argc > 1 ? -EINVAL : SHELL_CMD_HELP_PRINTED;
	}
	/* As the shell checks a static root: mandatory counts the command, 0 checks nothing. */
	if (root->args.mandatory != 0 &&
	    (argc < root->args.mandatory ||
	     (root->args.optional != SHELL_OPT_ARG_CHECK_SKIP &&
	      argc > (size_t)root->args.mandatory + root->args.optional))) {
		shell_error(sh, "%s: wrong parameter count", name);
		return -EINVAL;
	}
	return root->handler(sh, argc, argv);
}

#define PROXY(_name)                                                                               \
	static void UTIL_CAT(proxy_get_, _name)(size_t idx, struct shell_static_entry *entry)      \
	{                                                                                          \
		proxy_get(STRINGIFY(_name), idx, entry);                                           \
	}                                                                                          \
	SHELL_DYNAMIC_CMD_CREATE(UTIL_CAT(proxy_sub_, _name), UTIL_CAT(proxy_get_, _name));        \
	static int UTIL_CAT(proxy_cmd_, _name)(const struct shell *sh, size_t argc, char **argv)  \
	{                                                                                          \
		return proxy_cmd(STRINGIFY(_name), sh, argc, argv);                                \
	}                                                                                          \
	SHELL_CMD_ARG_REGISTER(_name, &UTIL_CAT(proxy_sub_, _name),                                \
			       "Command of the loaded app (app list)", UTIL_CAT(proxy_cmd_, _name), \
			       1, SHELL_OPT_ARG_CHECK_SKIP)

/* Every root command the apps register: hello, rfprobe, wpan, osmosdr and stream, link. */
PROXY(hello);
PROXY(probe);
PROXY(wpan);
PROXY(sdr);
PROXY(link);
PROXY(ofdm);

static int cmd_list(const struct shell *sh, size_t argc, char **argv)
{
	ARG_UNUSED(argc);
	ARG_UNUSED(argv);
	for (size_t i = 0; i < multiapp_embedded_count; i++) {
		const struct multiapp_embedded *app = &multiapp_embedded[i];
		char built_in[24] = "     -";
		char file[40] = "";
		ssize_t size;
		bool same;

		if (multiapp_drive_file(app->name, &size, &same) == 0) {
			if (size < 0) {
				(void)snprintf(file, sizeof(file), ", no file (%d)", (int)size);
			} else {
				(void)snprintf(file, sizeof(file), ", file %zd bytes%s", size,
					       same || app->elf == NULL ? "" : " (differs)");
			}
		}
		if (app->elf != NULL) {
			(void)snprintf(built_in, sizeof(built_in), "%6zu bytes", app->size);
		}
		shell_print(sh, "%-12s %s%s%s", app->name, built_in, file,
			    loaded_info != NULL && strcmp(loaded_info->name, app->name) == 0
				    ? ", running"
				    : "");
	}
	if (multiapp_drive_status() != 0) {
		shell_print(sh, "no FAT volume (%d)", multiapp_drive_status());
	}
	return 0;
}

static int cmd_run(const struct shell *sh, size_t argc, char **argv)
{
	int ret = multiapp_request(argv[1]);

	ARG_UNUSED(argc);
	if (ret == -ENOENT) {
		shell_error(sh, "%s: no such app (app list)", argv[1]);
	} else if (ret == 1) {
		shell_print(sh, "%s: rebooting into it%s", argv[1],
			    (usb_profile & MULTIAPP_USB_MSC) != 0U
				    ? " (eject the drive first: the PC may not have written it out)"
				    : "");
		ret = 0;
	} else if (ret != 0) {
		shell_error(sh, "%s: failed (%d)", argv[1], ret);
	} else {
		shell_print(sh, "%s: started", argv[1]);
	}
	return ret;
}

static int cmd_info(const struct shell *sh, size_t argc, char **argv)
{
	ARG_UNUSED(argc);
	ARG_UNUSED(argv);
	shell_print(sh, "host %s, build %02x%02x%02x%02x", APP_VERSION_STRING, build_id[0],
		    build_id[1], build_id[2], build_id[3]);
	if (main_size != 0U) {
		shell_print(sh, "host main: %zu of %zu bytes of stack used", main_used, main_size);
	}
	if (boot_name[0] != '\0') {
		shell_print(sh, "boot: %s, start %d, USB profile 0x%x", boot_name, boot_ret,
			    usb_profile);
	}
	if (loaded == NULL) {
		shell_print(sh, "no app loaded");
		return 0;
	}
	shell_print(sh, "%s (%s): text %zu at %p, data %zu, bss %zu, rodata %zu, %zu bytes in heaps",
		    loaded_info->name, loaded_source, loaded->mem_size[LLEXT_MEM_TEXT],
		    (void *)((uintptr_t)loaded->mem[LLEXT_MEM_TEXT] + IBUS_DBUS_OFFSET),
		    loaded->mem_size[LLEXT_MEM_DATA], loaded->mem_size[LLEXT_MEM_BSS],
		    loaded->mem_size[LLEXT_MEM_RODATA], loaded->alloc_size);
	for (size_t i = 0; i < root_count; i++) {
		shell_print(sh, "  command %s", roots[i]->syntax);
	}
	return 0;
}

/* What ended the previous boot, if it ended badly (apps/common app_crash.h). */
static int cmd_crash(const struct shell *sh, size_t argc, char **argv)
{
	struct app_crash_dx dx;
	struct app_crash c;
	size_t used, size;

	ARG_UNUSED(argc);
	ARG_UNUSED(argv);
	shell_print(sh, "reset reason cpu0 %d cpu1 %d (esp_rom_get_reset_reason())",
		    (int)esp_rom_get_reset_reason(0), (int)esp_rom_get_reset_reason(1));
	if (tried) {
		shell_print(sh, "the boot into %s ended at step %s", tried_name,
			    tried_step < ARRAY_SIZE(step_names) ? step_names[tried_step] : "?");
	}
	if (app_usb_dfu_stack(&used, &size)) {
		shell_print(sh, "last DFU download: %zu of %zu bytes of the USB thread's stack used",
			    used, size);
	}
	if (app_crash_dx_last(&dx)) {
		shell_print(sh, "double exception: depc 0x%08x exccause %u excvaddr 0x%08x"
			    " epc1 0x%08x ps 0x%08x a1 0x%08x prid 0x%x",
			    dx.depc, dx.exccause, dx.excvaddr, dx.epc1, dx.ps, dx.a1, dx.prid);
	}
	if (!app_crash_last(&c)) {
		shell_print(sh, "no fatal error or watchdog reset recorded");
		return 0;
	}
	if (c.reason == APP_CRASH_WATCHDOG) {
		shell_print(sh, "watchdog reset: thread %s cpu %u uptime %u ms", c.thread, c.cpu,
			    c.uptime_ms);
	} else {
		shell_print(sh, "fatal error %u: thread %s cpu %u uptime %u ms pc 0x%08x a0 0x%08x"
			    " ps 0x%08x exccause %u excvaddr 0x%08x",
			    c.reason, c.thread, c.cpu, c.uptime_ms, c.pc, c.a0, c.ps, c.exccause,
			    c.excvaddr);
	}
	return 0;
}

SHELL_STATIC_SUBCMD_SET_CREATE(app_cmds,
	SHELL_CMD(list, NULL, "The apps in this image", cmd_list),
	SHELL_CMD_ARG(run, NULL, "<name>: start an app (reboots if one runs)", cmd_run, 2, 0),
	SHELL_CMD(info, NULL, "The loaded app", cmd_info),
	SHELL_CMD(crash, NULL, "What ended the previous boot", cmd_crash),
	SHELL_SUBCMD_SET_END);
SHELL_CMD_REGISTER(app, &app_cmds, "Apps run as extensions", NULL);
```

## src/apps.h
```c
/*
 * SPDX-License-Identifier: GPL-3.0-or-later
 */

#ifndef MULTIAPP_APPS_H_
#define MULTIAPP_APPS_H_

#include <stdbool.h>
#include <stddef.h>
#include <stdint.h>
#include <sys/types.h>

/* An extension built with this image (embedded.c, generated by CMakeLists.txt). */
struct multiapp_embedded {
	const char *name;
	/* Its file (the ELF and its trailer), NULL without CONFIG_MULTIAPP_EMBEDDED. */
	const uint8_t *elf;
	size_t size;
	/* MULTIAPP_USB_*: the USB classes it needs. */
	uint32_t usb;
	/* Whether it has buffers in multiapp_area, which it then owns for the boot. */
	bool area;
};

extern const struct multiapp_embedded multiapp_embedded[];
extern const size_t multiapp_embedded_count;

const struct multiapp_embedded *multiapp_embedded_find(const char *name);

/* Load @p name and start its main(); -EBUSY once an app is loaded. */
int multiapp_start(const char *name);

/*
 * Start @p name now, or (returns 1) reboot into it: when an app is loaded or
 * USB runs another profile.
 */
int multiapp_request(const char *name);

/* At boot: start the app a request or CONFIG_MULTIAPP_AUTOSTART names; true if one runs. */
bool multiapp_boot(void);

/* A global function of the loaded app, by name (its hooks), or NULL. */
void *multiapp_app_fn(const char *name);

/* What an app's app_usb_init() calls: nothing to do (include/multiapp/ext.h). */
int multiapp_ext_usb_init(void);

/* Measure main()'s stack use as it returns, for "app info". */
void multiapp_note_main_stack(void);

/*
 * The apps as files on the FAT volume (drive.c). Only at boot, before USB
 * starts and before an app runs (its buffers are in bank 0).
 */
/* Mount, look up and check every built-in app's file, unmount; 0 or -errno (no volume). */
int multiapp_drive_scan(void);
/* The scan's result: 0, or why there is no volume. */
int multiapp_drive_status(void);
/* What the scan found for @p name: its size (or -errno) and whether it equals the built-in one. */
int multiapp_drive_file(const char *name, ssize_t *size, bool *same);
/* Hand the volume to the PC over USB (a boot without an app): ready the disk. */
int multiapp_drive_export(void);
/* Read @p name's file into @p buf: its size, or -errno. */
ssize_t multiapp_drive_read(const char *name, uint8_t *buf, size_t max);

#endif /* MULTIAPP_APPS_H_ */
```

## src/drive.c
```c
/*
 * SPDX-License-Identifier: GPL-3.0-or-later
 *
 * The apps as files: <name>.llext on the FAT volume (partition "fat", disk
 * "FLASH"). The host reads it only at boot, before USB and before an app:
 * the FATFS object, the flash disk cache and the drive's SCSI buffer are in
 * bank 0, which an app's ring overwrites. Reads go in chunks below a sector,
 * so the flash driver never gets a PSRAM buffer. A boot without an app lends
 * the volume to the PC as a USB drive; the DFU target "fat" writes it whole
 * (mkfat.py, west dfu --storage).
 */

#include <errno.h>
#include <stdio.h>
#include <string.h>

#include <ff.h>
#include <zephyr/fs/fs.h>
#include <zephyr/kernel.h>
#include <zephyr/logging/log.h>
#include <zephyr/storage/disk_access.h>
#include <zephyr/storage/flash_map.h>
#include <zephyr/storage/stream_flash.h>
#include <zephyr/usb/class/usbd_dfu.h>
#include <zephyr/usb/class/usbd_msc.h>
#include <zephyr/usb/usbd.h>

#include <esp_attr.h>

#include "app_usb.h"
#include "apps.h"

LOG_MODULE_DECLARE(multiapp, LOG_LEVEL_INF);

#define MOUNT_POINT "/FLASH:"
#define READ_CHUNK  256U
#define MAX_APPS    16U

static FATFS multiapp_fat_fs;
static struct fs_mount_t fat_mount = {
	.type = FS_FATFS,
	.mnt_point = MOUNT_POINT,
	.fs_data = &multiapp_fat_fs,
	.flags = FS_MOUNT_FLAG_READ_ONLY | FS_MOUNT_FLAG_NO_FORMAT,
};

/* What the boot's scan found: per built-in app, its file's size or -errno. */
static int drive_ret = -EAGAIN;
static ssize_t file_size[MAX_APPS];
static bool file_same[MAX_APPS];

static EXT_RAM_BSS_ATTR uint8_t chunk[READ_CHUNK];

static void file_path(char *path, size_t len, const char *name)
{
	(void)snprintf(path, len, "%s/%s.llext", MOUNT_POINT, name);
}

/* Read the open file into @p buf (up to @p max), or compare it with @p ref; bytes or -errno. */
static ssize_t read_file(struct fs_file_t *f, uint8_t *buf, size_t max, const uint8_t *ref,
			 bool *same)
{
	size_t done = 0;

	if (same != NULL) {
		*same = true;
	}
	for (;;) {
		ssize_t n = fs_read(f, chunk, sizeof(chunk));

		if (n < 0) {
			return n;
		}
		if (n == 0) {
			return (ssize_t)done;
		}
		if (buf != NULL) {
			if (done + (size_t)n > max) {
				return -EFBIG;
			}
			memcpy(buf + done, chunk, (size_t)n);
		}
		if (same != NULL && (done + (size_t)n > max || memcmp(ref + done, chunk, n) != 0)) {
			*same = false;
		}
		done += (size_t)n;
	}
}

int multiapp_drive_scan(void)
{
	char path[48];
	int ret;

	ret = fs_mount(&fat_mount);
	if (ret != 0) {
		drive_ret = ret;
		LOG_WRN("no FAT volume (%d)", ret);
		return ret;
	}
	for (size_t i = 0; i < multiapp_embedded_count && i < MAX_APPS; i++) {
		const struct multiapp_embedded *app = &multiapp_embedded[i];
		struct fs_file_t f;

		fs_file_t_init(&f);
		file_path(path, sizeof(path), app->name);
		ret = fs_open(&f, path, FS_O_READ);
		if (ret != 0) {
			file_size[i] = ret;
			continue;
		}
		file_size[i] = read_file(&f, NULL, app->size, app->elf,
					 app->elf != NULL ? &file_same[i] : NULL);
		(void)fs_close(&f);
	}
	(void)fs_unmount(&fat_mount);
	drive_ret = 0;
	return 0;
}

int multiapp_drive_status(void)
{
	return drive_ret;
}

int multiapp_drive_file(const char *name, ssize_t *size, bool *same)
{
	if (drive_ret != 0) {
		return drive_ret;
	}
	for (size_t i = 0; i < multiapp_embedded_count && i < MAX_APPS; i++) {
		if (strcmp(multiapp_embedded[i].name, name) == 0) {
			*size = file_size[i];
			*same = file_same[i];
			return 0;
		}
	}
	return -ENOENT;
}

USBD_DEFINE_MSC_LUN(fat, "FLASH", "ESP-SDR", "multiapp", "1.0");

int multiapp_drive_export(void)
{
	/* MSC reports no medium until the disk is initialized. */
	return disk_access_init("FLASH");
}

ssize_t multiapp_drive_read(const char *name, uint8_t *buf, size_t max)
{
	struct fs_file_t f;
	char path[48];
	ssize_t ret;

	ret = fs_mount(&fat_mount);
	if (ret != 0) {
		return ret;
	}
	fs_file_t_init(&f);
	file_path(path, sizeof(path), name);
	ret = fs_open(&f, path, FS_O_READ);
	if (ret == 0) {
		ret = read_file(&f, buf, max, NULL, NULL);
		(void)fs_close(&f);
	}
	(void)fs_unmount(&fat_mount);
	return ret;
}

/*
 * ---- DFU target "fat": the volume image ----
 *
 * stream_flash, not flash_img: that one writes an MCUboot image, from the
 * offset swap-using-offset gives the update slot. Pages are erased as the
 * writes reach them.
 */

static struct {
	struct stream_flash_ctx sf;
	uint8_t buf[CONFIG_USBD_DFU_TRANSFER_SIZE];
	uint32_t last_block;
	uint32_t uploaded;
	/* A download went to the volume, not to the image slot. */
	bool written;
} dfu;

static int fat_dfu_read(void *const priv, const uint32_t block, const uint16_t size,
			uint8_t buf[static CONFIG_USBD_DFU_TRANSFER_SIZE])
{
	const struct flash_area *fa;
	uint32_t len;
	int ret;

	ARG_UNUSED(priv);
	if (size == 0U) {
		return 0;
	}
	if (block == 0U) {
		dfu.uploaded = 0;
	} else if (dfu.last_block + 1U != block) {
		return -EINVAL;
	}
	ret = flash_area_open(PARTITION_ID(fat_partition), &fa);
	if (ret != 0) {
		return ret;
	}
	len = MIN((uint32_t)size, fa->fa_size - dfu.uploaded);
	ret = flash_area_read(fa, dfu.uploaded, buf, len);
	flash_area_close(fa);
	if (ret != 0) {
		return ret;
	}
	dfu.last_block = block;
	dfu.uploaded += len;
	return (int)len;
}

static int fat_dfu_write(void *const priv, const uint32_t block, const uint16_t size,
			 const uint8_t buf[static CONFIG_USBD_DFU_TRANSFER_SIZE])
{
	ARG_UNUSED(priv);
	if (block == 0U) {
		const struct flash_area *fa;
		int ret = flash_area_open(PARTITION_ID(fat_partition), &fa);

		if (ret != 0) {
			return ret;
		}
		ret = stream_flash_init(&dfu.sf, flash_area_get_device(fa), dfu.buf,
					sizeof(dfu.buf), fa->fa_off, fa->fa_size, NULL);
		flash_area_close(fa);
		if (ret != 0) {
			return ret;
		}
		dfu.written = true;
		if (size == 0U) {
			return 0;
		}
	} else if (dfu.last_block + 1U != block) {
		return -EINVAL;
	}
	dfu.last_block = block;
	/* Size 0 ends the download: write out what is buffered. */
	return stream_flash_buffered_write(&dfu.sf, buf, size, size == 0U);
}

static bool fat_dfu_next(void *const priv, const enum usb_dfu_state state,
			 const enum usb_dfu_state next)
{
	ARG_UNUSED(priv);
	ARG_UNUSED(state);
	ARG_UNUSED(next);
	return true;
}

USBD_DFU_DEFINE_IMG(fat_image, "fat", NULL, fat_dfu_read, fat_dfu_write, fat_dfu_next);

bool app_usb_dfu_was_slot(void)
{
	return !dfu.written;
}
```
